# EFR32ZG13P531F512GM48 register map
File version: 4.0.0
CPU: CM4 r0p1, little endian, MPU, FPU, 3 interrupt priority bits
Registers are 32-bit, read-write, reset 0x0 unless marked. A register's access mark holds for its fields unless they carry their own. Offsets are from the block's base; [hi:lo] are bit positions; {n}, {i} and the like mark numbered series.

## PRS
Base 0x400E6000
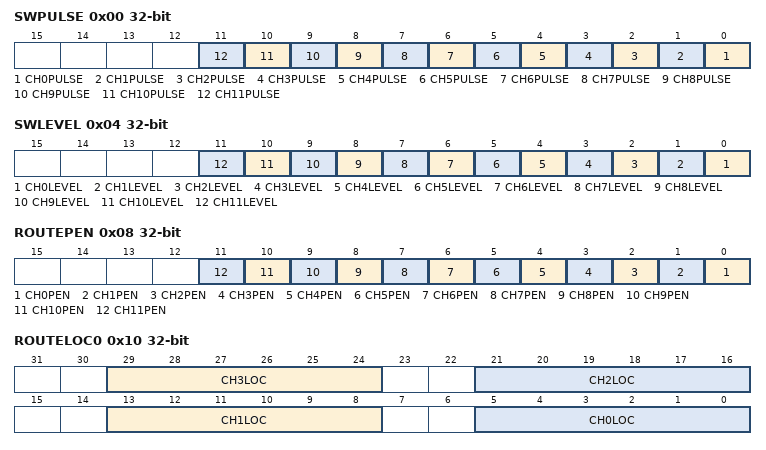
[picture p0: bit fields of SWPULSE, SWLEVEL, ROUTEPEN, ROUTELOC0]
0x00 SWPULSE wo — Software Pulse Register
  [n] CH{n}PULSE (n=0..11) — Channel {n} Pulse Generation
0x04 SWLEVEL — Software Level Register
  [n] CH{n}LEVEL (n=0..11) — Channel {n} Software Level
0x08 ROUTEPEN — I/O Routing Pin Enable Register
  [n] CH{n}PEN (n=0..11) — CH{n} Pin Enable
0x10 ROUTELOC0 — I/O Routing Location Register
  [29:24] CH3LOC — I/O Location
    {v}=LOC{v} (Location {v}) (v=0..14)
  [21:16] CH2LOC — I/O Location
    {v}=LOC{v} (Location {v}) (v=0..7)
  [13:8] CH1LOC — I/O Location
    {v}=LOC{v} (Location {v}) (v=0..7)
  [5:0] CH0LOC — I/O Location
    {v}=LOC{v} (Location {v}) (v=0..13)
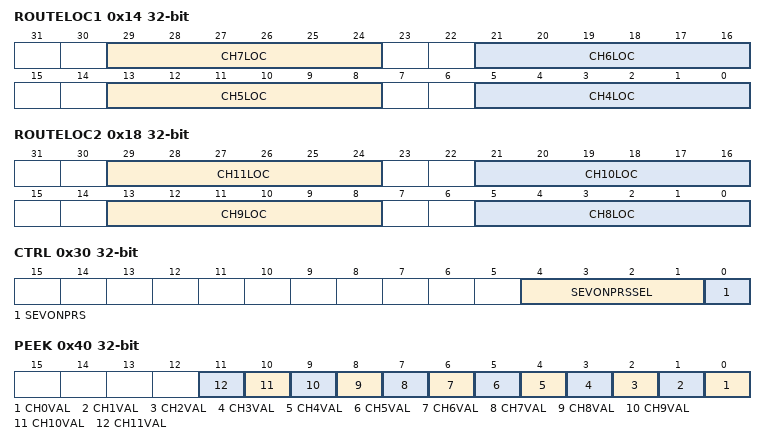
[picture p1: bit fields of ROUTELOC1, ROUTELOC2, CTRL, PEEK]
0x14 ROUTELOC1 — I/O Routing Location Register
  [29:24] CH7LOC — I/O Location
    {v}=LOC{v} (Location {v}) (v=0..10)
  [21:16] CH6LOC — I/O Location
    {v}=LOC{v} (Location {v}) (v=0..17)
  [13:8] CH5LOC — I/O Location
    {v}=LOC{v} (Location {v}) (v=0..6)
  [5:0] CH4LOC — I/O Location
    {v}=LOC{v} (Location {v}) (v=0..6)
0x18 ROUTELOC2 — I/O Routing Location Register
  [29:24] CH11LOC — I/O Location
    {v}=LOC{v} (Location {v}) (v=0..5)
  [21:16] CH10LOC — I/O Location
    {v}=LOC{v} (Location {v}) (v=0..5)
  [13:8] CH9LOC — I/O Location
    {v}=LOC{v} (Location {v}) (v=0..16)
  [5:0] CH8LOC — I/O Location
    {v}=LOC{v} (Location {v}) (v=0..10)
0x30 CTRL — Control Register
  [4:1] SEVONPRSSEL — SEVONPRS PRS Channel Select
    {v}=PRSCH{v} (PRS Channel {v} selected) (v=0..11)
  [0] SEVONPRS — Set Event on PRS
0x34 DMAREQ0 — DMA Request 0 Register
  [9:6] PRSSEL — DMA Request 0 PRS Channel Select
    {v}=PRSCH{v} (PRS Channel {v} selected) (v=0..11)
0x38 DMAREQ1 — DMA Request 1 Register
  [9:6] PRSSEL — DMA Request 1 PRS Channel Select
    {v}=PRSCH{v} (PRS Channel {v} selected) (v=0..11)
0x40 PEEK ro — PRS Channel Values
  [n] CH{n}VAL (n=0..11) — Channel {n} Current Value
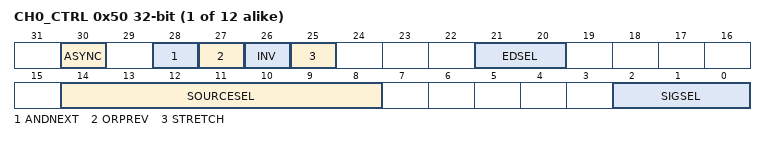
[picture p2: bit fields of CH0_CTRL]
{0x50+4i} CH{i}_CTRL (i=0..11) — Channel Control Register
  [30] ASYNC — Asynchronous Reflex
  [28] ANDNEXT
  [27] ORPREV — Or Previous
  [26] INV — Invert Channel
  [25] STRETCH — Stretch Channel Output
  [21:20] EDSEL — Edge Detect Select
    0=OFF (Signal is left as it is); 1=POSEDGE (A one HFCLK cycle pulse is generated for every positive edge of the incoming signal); 2=NEGEDGE (A one HFCLK clock cycle pulse is generated for every negative edge of the incoming signal); 3=BOTHEDGES (A one HFCLK clock cycle pulse is generated for every edge of the incoming signal)
  [14:8] SOURCESEL — Source Select
    0=NONE (No source selected); 1=PRSL (Peripheral Reflex System); 2=PRSH (Peripheral Reflex System); 3=ACMP0 (Analog Comparator 0); 4=ACMP1 (Analog Comparator 1); 5=ADC0 (Analog to Digital Converter 0); 7=LESENSEL (Low Energy Sensor Interface); 8=LESENSEH (Low Energy Sensor Interface); 9=LESENSED (Low Energy Sensor Interface); 10=LESENSE (Low Energy Sensor Interface); 11=RTCC (Real-Time Counter and Calendar); 12=GPIOL (General purpose Input/Output); 13=GPIOH (General purpose Input/Output); 14=LETIMER0 (Low Energy Timer 0); 15=PCNT0 (Pulse Counter 0); 16=PRORTC (Protocol Real-Time Counter); 18=CMU (Clock Management Unit); 24=VDAC0 (Digital to Analog Converter 0); 26=CRYOTIMER; 48=USART0 (Universal Synchronous/Asynchronous Receiver/Transmitter 0); 49=USART1 (Universal Synchronous/Asynchronous Receiver/Transmitter 1); 50=USART2 (Universal Synchronous/Asynchronous Receiver/Transmitter 2); 60=TIMER0; 61=TIMER1; 62=WTIMER0 (Wide Timer 0); 67=CM4
  [2:0] SIGSEL — Signal Select

## FPUEH
Base 0x400E1000
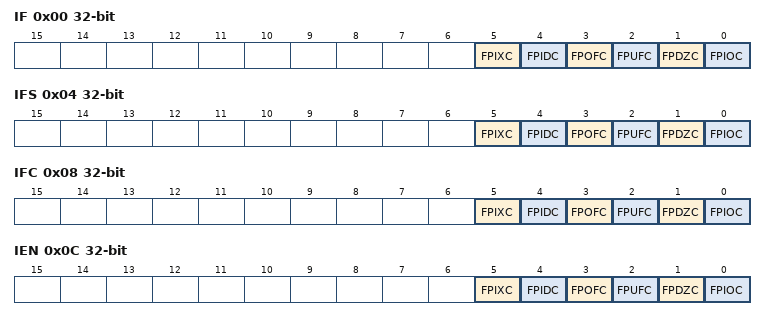
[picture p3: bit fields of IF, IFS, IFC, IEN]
0x00 IF ro — Interrupt Flag Register
  [5] FPIXC — FPU inexact exception
  [4] FPIDC — FPU input denormal exception
  [3] FPOFC — FPU overflow exception
  [2] FPUFC — FPU underflow exception
  [1] FPDZC — FPU divide-by-zero exception
  [0] FPIOC — FPU invalid operation
0x04 IFS wo — Interrupt Flag Set Register
  [5] FPIXC — Set FPIXC Interrupt Flag
  [4] FPIDC — Set FPIDC Interrupt Flag
  [3] FPOFC — Set FPOFC Interrupt Flag
  [2] FPUFC — Set FPUFC Interrupt Flag
  [1] FPDZC — Set FPDZC Interrupt Flag
  [0] FPIOC — Set FPIOC Interrupt Flag
0x08 IFC wo — Interrupt Flag Clear Register
  [5] FPIXC — Clear FPIXC Interrupt Flag
  [4] FPIDC — Clear FPIDC Interrupt Flag
  [3] FPOFC — Clear FPOFC Interrupt Flag
  [2] FPUFC — Clear FPUFC Interrupt Flag
  [1] FPDZC — Clear FPDZC Interrupt Flag
  [0] FPIOC — Clear FPIOC Interrupt Flag
0x0C IEN — Interrupt Enable Register
  [5] FPIXC — FPIXC Interrupt Enable
  [4] FPIDC — FPIDC Interrupt Enable
  [3] FPOFC — FPOFC Interrupt Enable
  [2] FPUFC — FPUFC Interrupt Enable
  [1] FPDZC — FPDZC Interrupt Enable
  [0] FPIOC — FPIOC Interrupt Enable

## Notices in the file
# License
Copyright 2021 Silicon Laboratories Inc. www.silabs.com
SPDX-License-Identifier: Zlib
The licensor of this software is Silicon Laboratories Inc.
This software is provided 'as-is', without any express or implied
warranty. In no event will the authors be held liable for any damages
arising from the use of this software.
Permission is granted to anyone to use this software for any purpose,
including commercial applications, and to alter it and redistribute it
freely, subject to the following restrictions:
1. The origin of this software must not be misrepresented; you must not
claim that you wrote the original software. If you use this software
in a product, an acknowledgment in the product documentation would be
appreciated but is not required.
2. Altered source versions must be plainly marked as such, and must not be
misrepresented as being the original software.
3. This notice may not be removed or altered from any source distribution.
